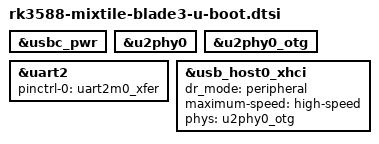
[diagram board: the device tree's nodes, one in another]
#include "rk3588-u-boot.dtsi"

/* Enable the type-c usb that is used for powering the board, so uboot can negotiate to 12V+ */
/* The base/kernel/upstream DT has it as "fail" */
/* uboot will later during fdt fixup enable it also for the kernel */
&usbc_pwr {
	status = "okay";
};

/* Make the non-power USB port work with gadget/UMS */
&u2phy0 {
	status = "okay";
};

&u2phy0_otg {
	status = "okay";
};

&uart2 {
	pinctrl-0 = <&uart2m0_xfer>;
	status = "okay";
};

&usb_host0_xhci {
	dr_mode = "peripheral";
	maximum-speed = "high-speed";
	phys = <&u2phy0_otg>;
	phy-names = "usb2-phy";
	status = "okay";
};
